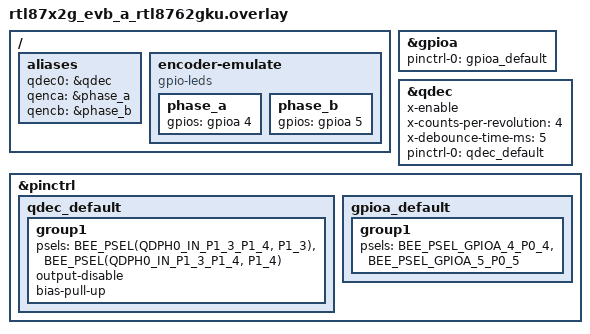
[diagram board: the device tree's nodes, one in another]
/*
 * Copyright (c) 2026, Realtek Semiconductor Corporation
 *
 * SPDX-License-Identifier: Apache-2.0
 */

/ {
	aliases {
		qdec0 = &qdec;
		qenca = &phase_a;
		qencb = &phase_b;
	};

	encoder-emulate {
		compatible = "gpio-leds";

		phase_a: phase_a {
			gpios = <&gpioa 4 GPIO_ACTIVE_HIGH>;
		};

		phase_b: phase_b {
			gpios = <&gpioa 5 GPIO_ACTIVE_HIGH>;
		};
	};
};

&gpioa {
	status = "okay";
	pinctrl-0 = <&gpioa_default>;
	pinctrl-names = "default";
};

&qdec {
	x-enable;
	x-counts-per-revolution = <4>;
	x-debounce-time-ms = <5>;
	pinctrl-0 = <&qdec_default>;
	pinctrl-names = "default";
	status = "okay";
};

&pinctrl {
	qdec_default: qdec_default {
		group1 {
			psels = <BEE_PSEL(QDPH0_IN_P1_3_P1_4, P1_3)>,
				<BEE_PSEL(QDPH0_IN_P1_3_P1_4, P1_4)>;
			output-disable;
			bias-pull-up;
		};
	};

	gpioa_default: gpioa_default {
		group1 {
			psels = <BEE_PSEL_GPIOA_4_P0_4>,
				<BEE_PSEL_GPIOA_5_P0_5>;
		};
	};
};
